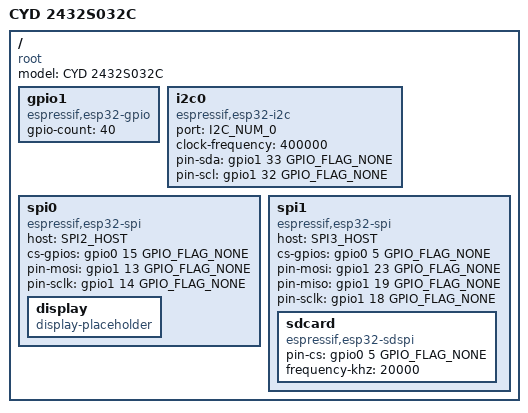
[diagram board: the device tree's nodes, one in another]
/dts-v1/;

#include <tactility/bindings/root.h>
#include <tactility/bindings/esp32_gpio.h>
#include <tactility/bindings/esp32_i2c.h>
#include <tactility/bindings/esp32_spi.h>
#include <tactility/bindings/esp32_sdspi.h>
#include <tactility/bindings/display_placeholder.h>

/ {
	compatible = "root";
	model = "CYD 2432S032C";

	gpio1 {
		compatible = "espressif,esp32-gpio";
		gpio-count = <40>;
	};

	i2c0 {
		compatible = "espressif,esp32-i2c";
		port = <I2C_NUM_0>;
		clock-frequency = <400000>;
		pin-sda = <&gpio1 33 GPIO_FLAG_NONE>;
		pin-scl = <&gpio1 32 GPIO_FLAG_NONE>;
	};

	spi0 {
		compatible = "espressif,esp32-spi";
		host = <SPI2_HOST>;
		cs-gpios = <&gpio0 15 GPIO_FLAG_NONE>;
		pin-mosi = <&gpio1 13 GPIO_FLAG_NONE>;
		pin-sclk = <&gpio1 14 GPIO_FLAG_NONE>;
	
		display {
			compatible = "display-placeholder";
		};
	};

	spi1 {
		compatible = "espressif,esp32-spi";
		host = <SPI3_HOST>;
		cs-gpios = <&gpio0 5 GPIO_FLAG_NONE>;
		pin-mosi = <&gpio1 23 GPIO_FLAG_NONE>;
		pin-miso = <&gpio1 19 GPIO_FLAG_NONE>;
		pin-sclk = <&gpio1 18 GPIO_FLAG_NONE>;
	
		sdcard {
			compatible = "espressif,esp32-sdspi";
			pin-cs = <&gpio0 5 GPIO_FLAG_NONE>;
			frequency-khz = <20000>;
		};
	};
};
